# MCF5441x register map
Vendor: NXP; File version: 1.0
Registers are 32-bit, read-write, reset 0x0 unless marked. A register's access mark holds for its fields unless they carry their own. Offsets are from the block's base; [hi:lo] are bit positions; {n}, {i} and the like mark numbered series; 'fields as' and 'values as' point back to an identical list.

## MCPWM
Base 0xEC088000
{0x0+0x50*i} SM{i}CNT 16-bit ro (i=0..3)
{0x2+0x50*i} SM{i}INIT 16-bit (i=0..3)
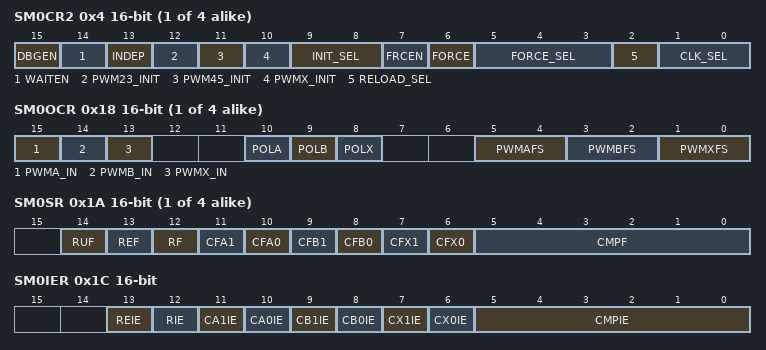
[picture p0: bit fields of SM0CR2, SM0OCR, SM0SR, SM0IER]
{0x4+0x50*i} SM{i}CR2 16-bit (i=0..3)
  [15] DBGEN, [14] WAITEN, [13] INDEP, [12] PWM23_INIT, [11] PWM45_INIT, [10] PWMX_INIT, [9:8] INIT_SEL, [7] FRCEN, [6] FORCE, [5:3] FORCE_SEL, [2] RELOAD_SEL, [1:0] CLK_SEL
{0x6+0x50*i} SM{i}CR1 16-bit (i=0..3)
{0x8+2i} SM0VAL{i} 16-bit (i=0..5)
  [15:0] VAL
{0x18+0x50*i} SM{i}OCR 16-bit reset not defined (i=0..3)
  [15] PWMA_IN, [14] PWMB_IN, [13] PWMX_IN, [10] POLA, [9] POLB, [8] POLX, [5:4] PWMAFS, [3:2] PWMBFS, [1:0] PWMXFS
{0x1A+0x50*i} SM{i}SR 16-bit (i=0..3)
  [14] RUF, [13] REF write-1-clears, [12] RF write-1-clears, [11] CFA1 write-1-clears, [10] CFA0 write-1-clears, [9] CFB1 write-1-clears, [8] CFB0 write-1-clears, [7] CFX1 write-1-clears, [6] CFX0 write-1-clears, [5:0] CMPF write-1-clears
0x1C SM0IER 16-bit
  [13] REIE, [12] RIE, [11] CA1IE, [10] CA0IE, [9] CB1IE, [8] CB0IE, [7] CX1IE, [6] CX0IE, [5:0] CMPIE
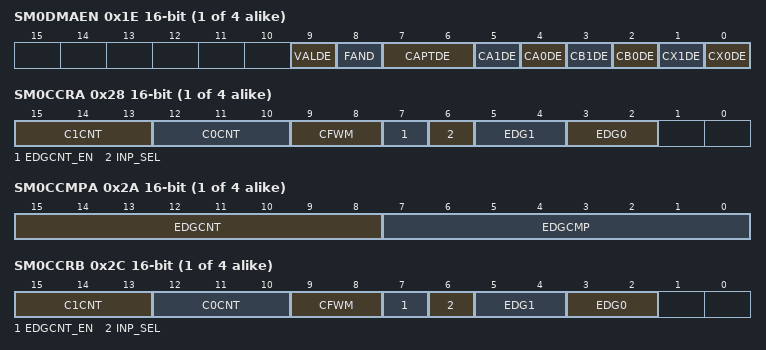
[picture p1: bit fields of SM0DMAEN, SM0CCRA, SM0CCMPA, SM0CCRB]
{0x1E+0x50*i} SM{i}DMAEN 16-bit (i=0..3)
  [9] VALDE
    0=DISABLED; 1=ENABLED
  [8] FAND
    0=OR_OPERATION_IS_USED; 1=AND_OPERATION_IS_USED
  [7:6] CAPTDE
  [5] CA1DE
  [4] CA0DE
  [3] CB1DE
  [2] CB0DE
  [1] CX1DE
  [0] CX0DE
{0x20+0x50*i} SM{i}OTCR 16-bit (i=0..3)
  [5:0] OTEN
{0x22+0x50*i} SM{i}DISMAP 16-bit reset 0xFFFF (i=0..3)
{0x24+0x50*i} SM{i}DTCNT0 16-bit reset 0x7FF (i=0..3)
  [10:0] DT
{0x26+0x50*i} SM{i}DTCNT1 16-bit reset 0x7FF (i=0..3)
  [10:0] DT
{0x28+0x50*i} SM{i}CCRA 16-bit (i=0..3)
  [15:13] C1CNT
  [12:10] C0CNT
  [9:8] CFWM
  [7] EDGCNT_EN
  [6] INP_SEL
  [5:4] EDG1
    0=DISABLED; 1=CAPTURE_FALLING_EDGES; 2=CAPTURE_RISING_EDGES; 3=CAPTURE_ANY_EDGE
  [3:2] EDG0
    values as EDG1
{0x2A+0x50*i} SM{i}CCMPA 16-bit (i=0..3)
  [15:8] EDGCNT, [7:0] EDGCMP
{0x2C+0x50*i} SM{i}CCRB 16-bit (i=0..3)
  fields as SM0CCRA
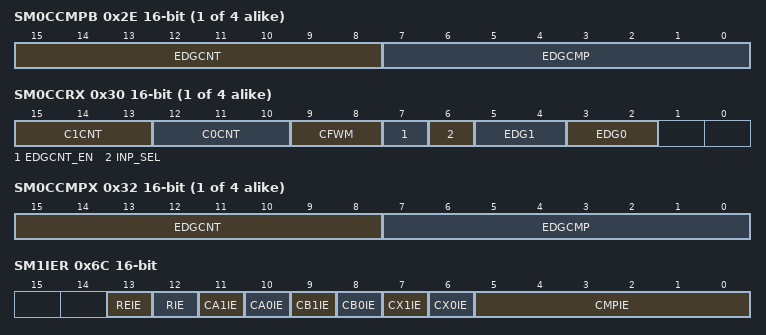
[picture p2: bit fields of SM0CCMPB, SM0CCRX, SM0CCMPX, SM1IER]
{0x2E+0x50*i} SM{i}CCMPB 16-bit (i=0..3)
  [15:8] EDGCNT, [7:0] EDGCMP
{0x30+0x50*i} SM{i}CCRX 16-bit (i=0..3)
  fields as SM0CCRA
{0x32+0x50*i} SM{i}CCMPX 16-bit (i=0..3)
  [15:8] EDGCNT, [7:0] EDGCMP
{0x34+4i} SM0CVAL{i} 16-bit ro (i=0..5)
{0x36+4i} SM0CCYC{i} 16-bit ro (i=0..4)
  [15:0] CYC
0x4A SMCCYC5 16-bit ro
  [15:0] CYC
{0x58+2i} SM1VAL{i} 16-bit (i=0..5)
  [15:0] VAL
0x6C SM1IER 16-bit
  fields as SM0IER
{0x84+4i} SM1CVAL{i} 16-bit ro (i=0..5)
{0x86+4i} SM1CCYC{i} 16-bit ro (i=0..4)
  [15:0] CYC
{0x4A+0x50*i} SM{i}CCYC5 16-bit ro reset not defined (i=1..3)
  [15:0] CYC
{0xA8+2i} SM2VAL{i} 16-bit (i=0..5)
  [15:0] VAL
0xBC SM2IER 16-bit
{0xD4+4i} SM2CVAL{i} 16-bit ro (i=0..5)
{0xD6+4i} SM2CCYC{i} 16-bit ro (i=0..4)
  [15:0] CYC
{0xF8+2i} SM3VAL{i} 16-bit (i=0..5)
  [15:0] VAL
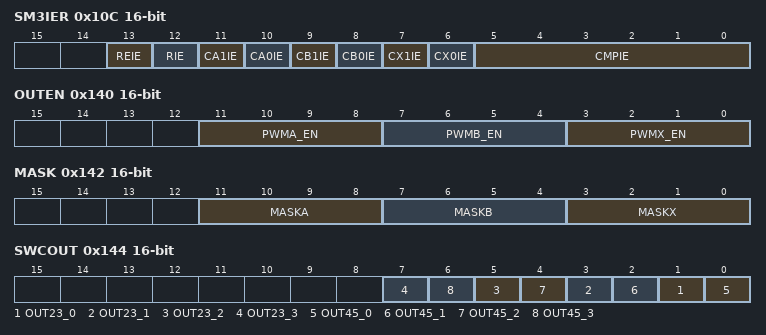
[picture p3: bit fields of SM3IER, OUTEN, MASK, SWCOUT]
0x10C SM3IER 16-bit
  fields as SM0IER
{0x124+4i} SM3CVAL{i} 16-bit ro (i=0..5)
{0x126+4i} SM3CCYC{i} 16-bit ro (i=0..4)
  [15:0] CYC
0x140 OUTEN 16-bit
  [11:8] PWMA_EN, [7:4] PWMB_EN, [3:0] PWMX_EN
0x142 MASK 16-bit
  [11:8] MASKA, [7:4] MASKB, [3:0] MASKX
0x144 SWCOUT 16-bit
  [2n+1] OUT23_{n} (n=0..3), [2n] OUT45_{n} (n=0..3)
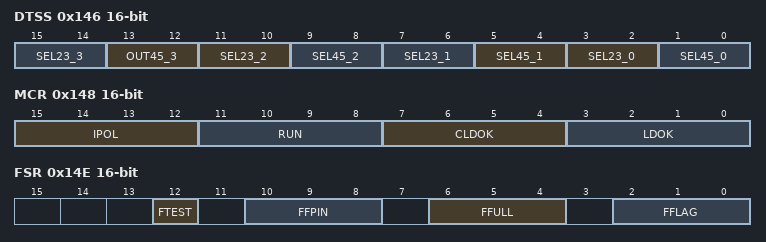
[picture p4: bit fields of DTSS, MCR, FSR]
0x146 DTSS 16-bit
  [4n+3:4n+2] SEL23_{n} (n=0..3), [13:12] OUT45_3, [9:8] SEL45_2, [5:4] SEL45_1, [1:0] SEL45_0
0x148 MCR 16-bit
  [15:12] IPOL, [11:8] RUN, [7:4] CLDOK, [3:0] LDOK
0x14C FCR 16-bit
0x14E FSR 16-bit reset not defined
  [12] FTEST, [10:8] FFPIN, [6:4] FFULL, [2:0] FFLAG
0x150 FFILT 16-bit

## NFC
Base 0xFC0FC000
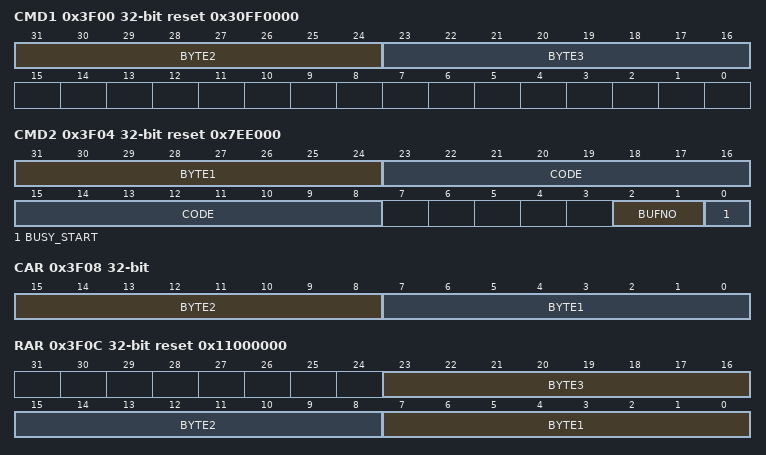
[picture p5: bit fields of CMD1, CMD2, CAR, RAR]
0x3F00 CMD1 reset 0x30FF0000
  [31:24] BYTE2, [23:16] BYTE3
0x3F04 CMD2 reset 0x7EE000
  [31:24] BYTE1, [23:8] CODE, [2:1] BUFNO, [0] BUSY_START
0x3F08 CAR
  [15:8] BYTE2, [7:0] BYTE1
0x3F0C RAR reset 0x11000000
  [23:16] BYTE3, [15:8] BYTE2, [7:0] BYTE1
0x3F10 RPT
  [15:0] COUNT
0x3F14 RAI reset 0x1
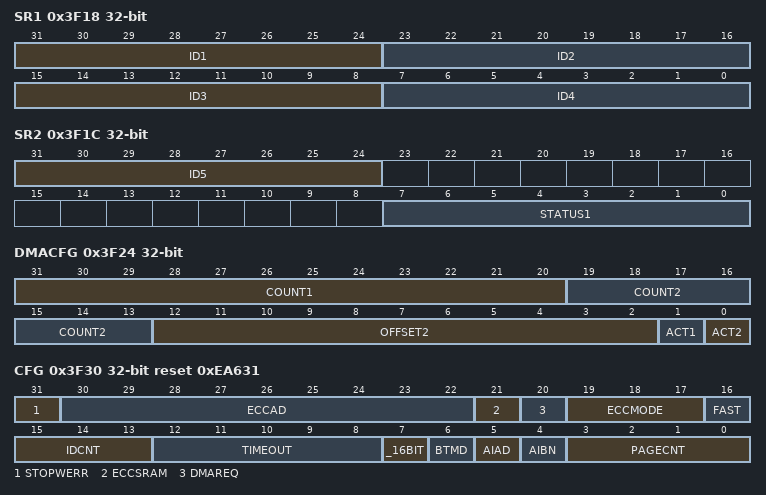
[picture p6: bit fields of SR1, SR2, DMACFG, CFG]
0x3F18 SR1 ro
  [39-8n:32-8n] ID{n} (n=1..4)
0x3F1C SR2 ro
  [31:24] ID5, [7:0] STATUS1
0x3F20 DMA1
  [31:0] ADDRESS
0x3F24 DMACFG
  [31:20] COUNT1, [19:13] COUNT2, [12:2] OFFSET2, [1] ACT1, [0] ACT2
0x3F28 SWAP reset 0xFFE0FFE
0x3F2C SECSZ reset 0x420
0x3F30 CFG reset 0xEA631
  [31] STOPWERR
  [30:22] ECCAD
  [21] ECCSRAM
  [20] DMAREQ
  [19:17] ECCMODE
  [16] FAST
  [15:13] IDCNT
  [12:8] TIMEOUT
  [7] _16BIT
  [6] BTMD
    0=NORMAL_MODE; 1=BOOT_MODE
  [5] AIAD
  [4] AIBN
  [3:0] PAGECNT
0x3F34 DMA2
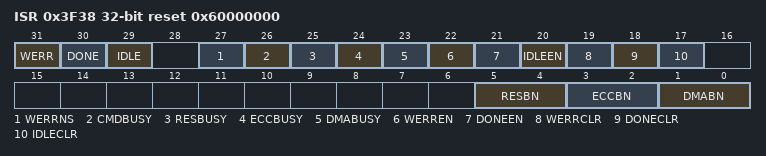
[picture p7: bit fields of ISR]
0x3F38 ISR reset 0x60000000
  [31] WERR, [30] DONE, [29] IDLE, [27] WERRNS, [26] CMDBUSY, [25] RESBUSY, [24] ECCBUSY, [23] DMABUSY, [22] WERREN, [21] DONEEN, [20] IDLEEN, [19] WERRCLR, [18] DONECLR, [17] IDLECLR, [5:4] RESBN, [3:2] ECCBN, [1:0] DMABN
